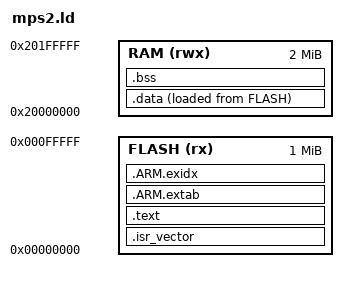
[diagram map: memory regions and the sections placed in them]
/* QEMU mps2-an385: code SRAM at 0, data SRAM at 0x20000000. */
MEMORY
{
  FLASH (rx)  : ORIGIN = 0x00000000, LENGTH = 1024K
  RAM   (rwx) : ORIGIN = 0x20000000, LENGTH = 2048K
}

ENTRY(Reset_Handler)

_estack = ORIGIN(RAM) + LENGTH(RAM);
_heap_end = _estack - 64K;

SECTIONS
{
  .isr_vector : { . = ALIGN(4); KEEP(*(.isr_vector)) . = ALIGN(4); } > FLASH
  .text : { . = ALIGN(4); *(.text*) *(.rodata*) *(.glue_7) *(.glue_7t) . = ALIGN(4); } > FLASH
  .ARM.extab : { *(.ARM.extab* .gnu.linkonce.armextab.*) } > FLASH
  .ARM.exidx : { __exidx_start = .; *(.ARM.exidx*) __exidx_end = .; } > FLASH
  _sidata = LOADADDR(.data);
  .data : { . = ALIGN(4); _sdata = .; *(.data*) . = ALIGN(4); _edata = .; } > RAM AT> FLASH
  .bss (NOLOAD) : { . = ALIGN(4); _sbss = .; *(.bss*) *(COMMON) . = ALIGN(8); _ebss = .; } > RAM
  _heap_start = _ebss;
  .ARM.attributes 0 : { *(.ARM.attributes) }
}
